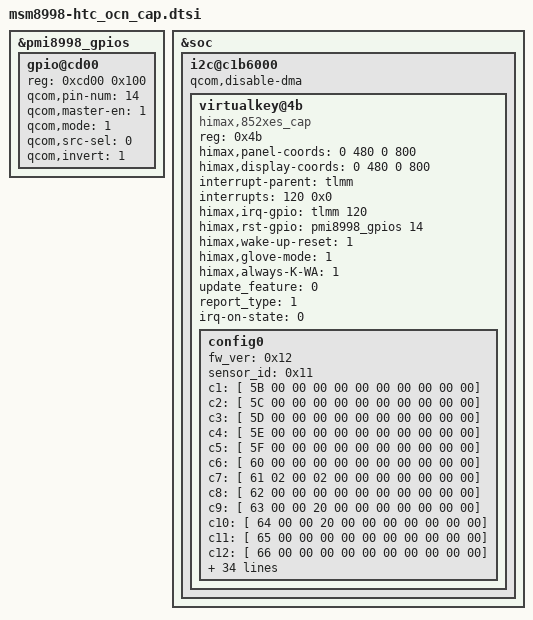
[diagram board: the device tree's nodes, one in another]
&pmi8998_gpios {
	gpio@cd00 {
		reg = <0xcd00 0x100>;
		qcom,pin-num = <14>;
		qcom,master-en = <1>;	/* Enable GPIO */
		qcom,mode = <1>;
		qcom,src-sel = <0>;	/* GPIO */
		qcom,invert = <1>;	/* output-high */
		status = "ok";
       };
};
&soc {
	i2c@c1b6000 {
		status = "ok";
		qcom,disable-dma;
		virtualkey@4b {
			compatible              = "himax,852xes_cap";
			reg                     = <0x4b>;
			himax,panel-coords      = <0 480 0 800>;
			himax,display-coords    = <0 480 0 800>;
			interrupt-parent = <&tlmm>;
			interrupts = <120 0x0>;
			himax,irq-gpio          = <&tlmm 120 0x0>;
			himax,rst-gpio          = <&pmi8998_gpios 14 0x0>;
			himax,wake-up-reset     = <1>;
			himax,glove-mode        = <1>;
			himax,always-K-WA       = <1>;
			update_feature          = <0>;
			report_type             = <1>;
			irq-on-state 		= <0>;

		config0 {
			fw_ver		= <0x12>;
			sensor_id	= <0x11>;
			c1  = [ 5B 00 00 00 00 00 00 00 00 00 00];
			c2  = [ 5C 00 00 00 00 00 00 00 00 00 00];
			c3  = [ 5D 00 00 00 00 00 00 00 00 00 00];
			c4  = [ 5E 00 00 00 00 00 00 00 00 00 00];
			c5  = [ 5F 00 00 00 00 00 00 00 00 00 00];
			c6  = [ 60 00 00 00 00 00 00 00 00 00 00];
			c7  = [ 61 02 00 02 00 00 00 00 00 00 00];
			c8  = [ 62 00 00 00 00 00 00 00 00 00 00];
			c9  = [ 63 00 00 20 00 00 00 00 00 00 00];
			c10 = [ 64 00 00 20 00 00 00 00 00 00 00];
			c11 = [ 65 00 00 00 00 00 00 00 00 00 00];
			c12 = [ 66 00 00 00 00 00 00 00 00 00 00];
			c13 = [ 67 00 00 00 00 00 00 00 00 00 00];
			c14 = [ 68 00 00 00 00 00 00 00 00 00 00];
			c15 = [ 69 00 00 00 00 00 00 00 00 00 00];
			c16 = [ 6A 00 00 00 00 00 00 00 00 00 00];
			c17 = [ 6B 01 00 01 00 00 00 00 00 00 00];
			c18 = [ D5 09 00 00 00 00 00 00 00 00 00
				00 00 00 00 00 00];
			c19 = [ E1 08 01 01 01 01 01 0F 01 0F 01 0F 01 0F 08]; //
			c20 = [ BC 00 00 00 00]; //
			c21 = [ C5 06 11 00 10 1A 1E 0B 11 02 1F]; //Self Setting
			c22 = [ C6 15 10 19]; //Mutual Setting
			c23 = [ BD 00 0B]; //SETCLK12
			c24 = [ B9 01 05]; //SET CVDD
			c25 = [ EC 10 DF 8D]; //SET PTBA
			c26 = [ B0 00]; //TX Floating
			c27 = [ DD 03]; //Set Cache
			c28 = [ 42 02]; //Reload Disable
			c29 = [ CE 00]; //HW Watch Dog
			c30 = [ CA 00]; //ESD Detector
			c31 = [ 3F 00]; //Dual Mode
			c32 = [ EB 03]; //SET AP
			c33 = [ BA 00]; //SET EQ
			c34 = [ BB 00]; //D0200 added.
			c35 = [ D3 06 01]; //TX Pumping Postivite
			c36 = [ 37 FF 08 FF 08]; //POWRSTB
			c37 = [ A4 94 62 94 86]; //Dual Mode
			c38 = [ ED 00 04 0A 0A 04 00 00 00]; //SET CLK
			c39 = [ CB 00 0F 0F FF FF 01 00 1F
				00 32 00 FF 00]; //GPIO_EN
			c40 = [ 40 00 5A //Customer Info
				04 00 68 14 41 00 //Switch
				3C 0C 0A 10 0A 0A 0A 0F 0F 0F //Threshold
				18 14 40 40 24 00 00 00 00 00 00 00 //Weighting
				63 0A F0 83 83 00 //Stability
				15 12 0F 0F 83 3C 00 00 //Palm
				11 00 41 42 //Enter
				10 10 00 04 00 00 //CCL
				0A 01 1E 64 00 00 //Timer
				18 1F 1F 05 15 00 00 00 //OSR Hopping
				04 06 24 07 07 00 00 00 //TX Hopping
				2B 50 0A 2F 10 DF 8D 20 00 02
				03 10 00 2E 00 00 //Idle
				08 00 40 00 00 00 02 10 //Water
				10 00 20 18 03 07 0B 00 //MKey
				BE 5A 28 00 //Bank
				02 01 20 12 //Channel
				00 02 00 82 00 82 //Resolution
				00 00 00 00 82 00 00 00 00 00 00 82 00 00 //Fitting Curve 1
				00 00 00 00 82 00 00 00 00 00 00 82 00 00 //Fitting Curve 2
				00 00 00 00 00 00 00 00]; //OLM Gen1 Pattern
			c41 = [ 40 FF FF FF FF FF FF FF FF FF FF
				FF FF FF FF FF FF 01
				FF FF FF FF FF FF 00 FF 03 02
				FF FF FF FF FF FF FF
				FF FF FF FF FF FF FF FF FF FF
				FF FF FF FF FF FF FF
				FF FF FF
				00 00 00 00 00 00 //Noise Matrix
				00 00 00 00 00 00 //Reserve
				00 00 00 00 00 00 //Reserve
				1A 7D 12 32 82 C2 05 00//Sensor Hub Gesture for HTC
				11 C4 45 C5 48 5C 03 55 00 00//High Sensitivity Mode
				00 00 00 00 00 00 //Reserve
				00 00]; //Checksum
			};
		};
	};
};
